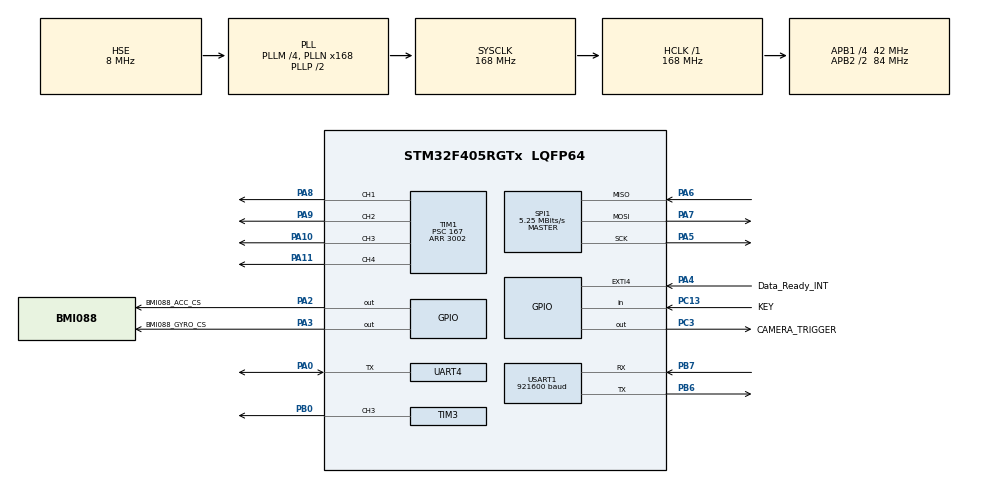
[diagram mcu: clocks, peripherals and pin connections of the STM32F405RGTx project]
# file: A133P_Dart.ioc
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Dma.Request0=USART1_RX
Dma.Request1=USART1_TX
Dma.USART1_RX.0.Direction=DMA_PERIPH_TO_MEMORY
Dma.USART1_RX.0.FIFOMode=DMA_FIFOMODE_DISABLE
Dma.USART1_RX.0.Instance=DMA2_Stream2
Dma.USART1_RX.0.MemDataAlignment=DMA_MDATAALIGN_BYTE
Dma.USART1_RX.0.MemInc=DMA_MINC_ENABLE
Dma.USART1_RX.0.Mode=DMA_CIRCULAR
Dma.USART1_RX.0.PeriphDataAlignment=DMA_PDATAALIGN_BYTE
Dma.USART1_RX.0.PeriphInc=DMA_PINC_DISABLE
Dma.USART1_RX.0.Priority=DMA_PRIORITY_LOW
Dma.USART1_TX.1.Direction=DMA_MEMORY_TO_PERIPH
Dma.USART1_TX.1.FIFOMode=DMA_FIFOMODE_DISABLE
Dma.USART1_TX.1.Instance=DMA2_Stream7
Dma.USART1_TX.1.MemDataAlignment=DMA_MDATAALIGN_BYTE
Dma.USART1_TX.1.MemInc=DMA_MINC_ENABLE
Dma.USART1_TX.1.Mode=DMA_NORMAL
Dma.USART1_TX.1.PeriphDataAlignment=DMA_PDATAALIGN_BYTE
Dma.USART1_TX.1.PeriphInc=DMA_PINC_DISABLE
Dma.USART1_TX.1.Priority=DMA_PRIORITY_LOW
Mcu.Family=STM32F4
Mcu.Name=STM32F405RGTx
Mcu.Package=LQFP64
NVIC.DMA2_Stream2_IRQn=true\:0\:0\:false\:false\:true\:false\:true\:true
NVIC.DMA2_Stream7_IRQn=true\:0\:0\:false\:false\:true\:false\:true\:true
NVIC.EXTI4_IRQn=true\:3\:0\:true\:false\:true\:true\:true\:true
NVIC.PriorityGroup=NVIC_PRIORITYGROUP_4
NVIC.TIM5_IRQn=true\:0\:0\:false\:false\:true\:true\:true\:true
NVIC.UART4_IRQn=true\:4\:0\:true\:false\:true\:true\:true\:true
NVIC.USART1_IRQn=true\:2\:0\:true\:false\:true\:true\:true\:true
PA0-WKUP.GPIO_PuPd=GPIO_PULLUP
PA0-WKUP.GPIO_Speed=GPIO_SPEED_FREQ_HIGH
PA0-WKUP.Mode=Half_duplex(single_wire_mode)
PA0-WKUP.Signal=UART4_TX
PA10.Signal=S_TIM1_CH3
PA11.Signal=S_TIM1_CH4
PA13.Mode=Serial_Wire
PA13.Signal=SYS_JTMS-SWDIO
PA14.Mode=Serial_Wire
PA14.Signal=SYS_JTCK-SWCLK
PA2.GPIO_Label=BMI088_ACC_CS
PA2.PinState=GPIO_PIN_SET
PA2.Signal=GPIO_Output
PA3.GPIO_Label=BMI088_GYRO_CS
PA3.PinState=GPIO_PIN_SET
PA3.Signal=GPIO_Output
PA4.GPIO_Label=Data_Ready_INT
PA4.Signal=GPXTI4
PA5.Mode=Full_Duplex_Master
PA5.Signal=SPI1_SCK
PA6.Mode=Full_Duplex_Master
PA6.Signal=SPI1_MISO
PA7.Mode=Full_Duplex_Master
PA7.Signal=SPI1_MOSI
PA8.Signal=S_TIM1_CH1
PA9.Signal=S_TIM1_CH2
PB0.Signal=S_TIM3_CH3
PB6.Mode=Asynchronous
PB6.Signal=USART1_TX
PB7.Mode=Asynchronous
PB7.Signal=USART1_RX
PC13-ANTI_TAMP.GPIO_Label=KEY
PC13-ANTI_TAMP.GPIO_PuPd=GPIO_PULLUP
PC13-ANTI_TAMP.Signal=GPIO_Input
PC3.GPIO_Label=CAMERA_TRIGGER
PC3.Signal=GPIO_Output
PH0-OSC_IN.Mode=HSE-External-Oscillator
PH0-OSC_IN.Signal=RCC_OSC_IN
PH1-OSC_OUT.Mode=HSE-External-Oscillator
PH1-OSC_OUT.Signal=RCC_OSC_OUT
ProjectManager.HeapSize=0x200
ProjectManager.StackSize=0x1000
ProjectManager.TargetToolchain=MDK-ARM V5.32
RCC.48MHZClocksFreq_Value=48000000
RCC.AHBFreq_Value=168000000
RCC.APB1CLKDivider=RCC_HCLK_DIV4
RCC.APB1Freq_Value=42000000
RCC.APB1TimFreq_Value=84000000
RCC.APB2CLKDivider=RCC_HCLK_DIV2
RCC.APB2Freq_Value=84000000
RCC.APB2TimFreq_Value=168000000
RCC.CortexFreq_Value=168000000
RCC.HCLKFreq_Value=168000000
RCC.HSE_VALUE=8000000
RCC.HSI_VALUE=16000000
RCC.LSE_VALUE=32768
RCC.PLLM=4
RCC.PLLN=168
RCC.PLLQ=7
RCC.PLLSourceVirtual=RCC_PLLSOURCE_HSE
RCC.SYSCLKFreq_VALUE=168000000
RCC.SYSCLKSource=RCC_SYSCLKSOURCE_PLLCLK
RCC.VCOOutputFreq_Value=336000000
SH.S_TIM1_CH1.0=TIM1_CH1,PWM Generation1 CH1
SH.S_TIM1_CH2.0=TIM1_CH2,PWM Generation2 CH2
SH.S_TIM1_CH3.0=TIM1_CH3,PWM Generation3 CH3
SH.S_TIM1_CH4.0=TIM1_CH4,PWM Generation4 CH4
SH.S_TIM3_CH3.0=TIM3_CH3,PWM Generation3 CH3
SPI1.BaudRatePrescaler=SPI_BAUDRATEPRESCALER_16
SPI1.CLKPhase=SPI_PHASE_2EDGE
SPI1.CLKPolarity=SPI_POLARITY_HIGH
SPI1.CalculateBaudRate=5.25 MBits/s
SPI1.Direction=SPI_DIRECTION_2LINES
SPI1.Mode=SPI_MODE_MASTER
SPI1.VirtualType=VM_MASTER
TIM1.Channel-PWM\ Generation1\ CH1=TIM_CHANNEL_1
TIM1.Channel-PWM\ Generation2\ CH2=TIM_CHANNEL_2
TIM1.Channel-PWM\ Generation3\ CH3=TIM_CHANNEL_3
TIM1.Channel-PWM\ Generation4\ CH4=TIM_CHANNEL_4
TIM1.Period=3002
TIM1.Prescaler=167
TIM1.Pulse-PWM\ Generation1\ CH1=1500
TIM1.Pulse-PWM\ Generation2\ CH2=1500
TIM1.Pulse-PWM\ Generation3\ CH3=1500
TIM1.Pulse-PWM\ Generation4\ CH4=1500
TIM3.Channel-PWM\ Generation3\ CH3=TIM_CHANNEL_3
TIM5.Period=999
TIM5.Prescaler=83
UART4.BaudRate=921600
UART4.VirtualMode=Asynchronous
USART1.BaudRate=921600
USART1.VirtualMode=VM_ASYNC
VP_TIM1_VS_ClockSourceINT.Mode=Internal
VP_TIM3_VS_ClockSourceINT.Mode=Internal
VP_TIM5_VS_ClockSourceINT.Mode=Internal
board=custom

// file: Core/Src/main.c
/* USER CODE BEGIN Header */
/**
  ******************************************************************************
  * @file           : main.c
  * @brief          : Main program body
  ******************************************************************************
  * @attention
  *
  * Copyright (c) 2026 STMicroelectronics.
  * All rights reserved.
  *
  * This software is licensed under terms that can be found in the LICENSE file
  * in the root directory of this software component.
  * If no LICENSE file comes with this software, it is provided AS-IS.
  *
  ******************************************************************************
  */
/* USER CODE END Header */
#include "main.h"
#include "dma.h"
#include "spi.h"
#include "tim.h"
#include "usart.h"
#include "gpio.h"

/* USER CODE BEGIN Includes */
#include "task_bridge.h"

/* USER CODE END Includes */

void SystemClock_Config(void);

int main(void)
{

  /* MCU Configuration--------------------------------------------------------*/

  /* Reset of all peripherals, Initializes the Flash interface and the Systick. */
  HAL_Init();

  /* Configure the system clock */
  SystemClock_Config();

  /* Initialize all configured peripherals */
  MX_GPIO_Init();
  MX_DMA_Init();
  MX_USART1_UART_Init();
  MX_SPI1_Init();
  MX_TIM1_Init();
  MX_TIM3_Init();
  MX_TIM5_Init();
  MX_UART4_Init();
  /* USER CODE BEGIN 2 */

  //HAL_Delay(9000);

  Task_Init();

  /* USER CODE END 2 */

  /* Infinite loop */
  while (1)
  {

    /* USER CODE BEGIN 3 */
    Task_Loop();
  }
  /* USER CODE END 3 */
}

void SystemClock_Config(void)
{
  RCC_OscInitTypeDef RCC_OscInitStruct = {0};
  RCC_ClkInitTypeDef RCC_ClkInitStruct = {0};

  /** Configure the main internal regulator output voltage
  */
  __HAL_RCC_PWR_CLK_ENABLE();
  __HAL_PWR_VOLTAGESCALING_CONFIG(PWR_REGULATOR_VOLTAGE_SCALE1);

  /** Initializes the RCC Oscillators according to the specified parameters
  * in the RCC_OscInitTypeDef structure.
  */
  RCC_OscInitStruct.OscillatorType = RCC_OSCILLATORTYPE_HSE;
  RCC_OscInitStruct.HSEState = RCC_HSE_ON;
  RCC_OscInitStruct.PLL.PLLState = RCC_PLL_ON;
  RCC_OscInitStruct.PLL.PLLSource = RCC_PLLSOURCE_HSE;
  RCC_OscInitStruct.PLL.PLLM = 4;
  RCC_OscInitStruct.PLL.PLLN = 168;
  RCC_OscInitStruct.PLL.PLLP = RCC_PLLP_DIV2;
  RCC_OscInitStruct.PLL.PLLQ = 7;
  if (HAL_RCC_OscConfig(&RCC_OscInitStruct) != HAL_OK)
  {
    Error_Handler();
  }

  /** Initializes the CPU, AHB and APB buses clocks
  */
  RCC_ClkInitStruct.ClockType = RCC_CLOCKTYPE_HCLK|RCC_CLOCKTYPE_SYSCLK
                              |RCC_CLOCKTYPE_PCLK1|RCC_CLOCKTYPE_PCLK2;
  RCC_ClkInitStruct.SYSCLKSource = RCC_SYSCLKSOURCE_PLLCLK;
  RCC_ClkInitStruct.AHBCLKDivider = RCC_SYSCLK_DIV1;
  RCC_ClkInitStruct.APB1CLKDivider = RCC_HCLK_DIV4;
  RCC_ClkInitStruct.APB2CLKDivider = RCC_HCLK_DIV2;

  if (HAL_RCC_ClockConfig(&RCC_ClkInitStruct, FLASH_LATENCY_5) != HAL_OK)
  {
    Error_Handler();
  }
}

void Error_Handler(void)
{
  __disable_irq();
  while (1)
  {
  }
}
